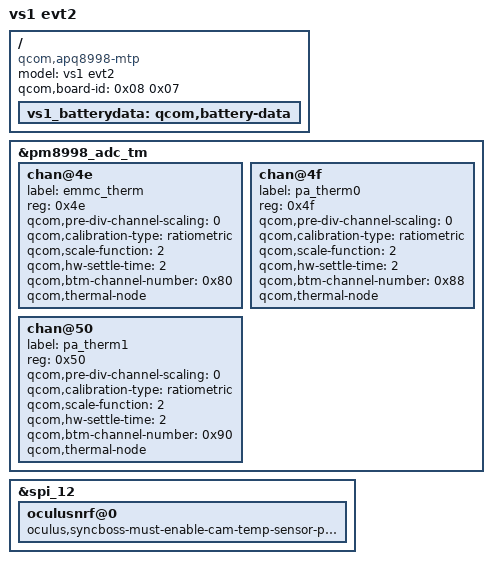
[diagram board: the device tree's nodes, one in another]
/* Copyright (c) 2016, The Linux Foundation. All rights reserved.
 *
 * This program is free software; you can redistribute it and/or modify
 * it under the terms of the GNU General Public License version 2 and
 * only version 2 as published by the Free Software Foundation.
 *
 * This program is distributed in the hope that it will be useful,
 * but WITHOUT ANY WARRANTY; without even the implied warranty of
 * MERCHANTABILITY or FITNESS FOR A PARTICULAR PURPOSE.  See the
 * GNU General Public License for more details.
 */


/dts-v1/;

#include "vs1-evt.dtsi"

/ {
	model = "vs1 evt2";
	compatible = "qcom,apq8998-mtp", "qcom,apq8998", "qcom,mtp";
	qcom,board-id = <0x08 0x07>;

	vs1_batterydata: qcom,battery-data {
		#include "3313509_Pegatron_VS1scud_4000mAh_averaged_MasterSlave_May15th2018_PMI8998GUI20058.dtsi"
	};
};

&pm8998_adc_tm {
	chan@4e {
		label = "emmc_therm";
		reg = <0x4e>;
		qcom,pre-div-channel-scaling = <0>;
		qcom,calibration-type = "ratiometric";
		qcom,scale-function = <2>;
		qcom,hw-settle-time = <2>;
		qcom,btm-channel-number = <0x80>;
		qcom,thermal-node;
	};

	chan@4f {
		label = "pa_therm0";
		reg = <0x4f>;
		qcom,pre-div-channel-scaling = <0>;
		qcom,calibration-type = "ratiometric";
		qcom,scale-function = <2>;
		qcom,hw-settle-time = <2>;
		qcom,btm-channel-number = <0x88>;
		qcom,thermal-node;
	};

	chan@50 {
		label = "pa_therm1";
		reg = <0x50>;
		qcom,pre-div-channel-scaling = <0>;
		qcom,calibration-type = "ratiometric";
		qcom,scale-function = <2>;
		qcom,hw-settle-time = <2>;
		qcom,btm-channel-number = <0x90>;
		qcom,thermal-node;
	};
};

&spi_12 {
	oculusnrf@0 {
		oculus,syncboss-must-enable-cam-temp-sensor-power;
	};
};
